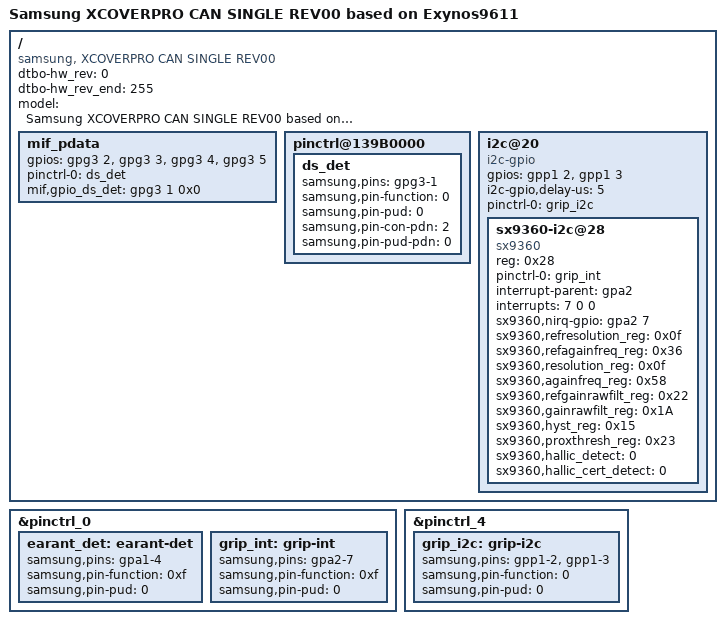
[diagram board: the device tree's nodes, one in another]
/*
 * SAMSUNG EXYNOS9610 board device tree source
 *
 * Copyright (c) 2018 Samsung Electronics Co., Ltd.
 *		http://www.samsung.com
 *
 * This program is free software; you can redistribute it and/or modify
 * it under the terms of the GNU General Public License version 2 as
 * published by the Free Software Foundation.
 */

/dts-v1/;
/plugin/;
#include "exynos9611-xcoverpro_common.dtsi"
#include "battery_data_xcoverpro_usa_open_00.dtsi"
#include "exynos9611-xcoverpro_fingerprint_00.dtsi"
#include "exynos9611-xcoverpro_sensorhub_00.dtsi"
#include "exynos9611-xcoverpro_nfc_00.dtsi"
#include "exynos9611-xcoverpro_can_single_gpio_00.dtsi"

/ {
	compatible = "samsung, XCOVERPRO CAN SINGLE REV00", "samsung,EXYNOS9611";
	dtbo-hw_rev = <0>;
	dtbo-hw_rev_end = <255>;

	fragment@model {
		target-path = "/";
		__overlay__ {
			#address-cells = <2>;
			#size-cells = <1>;

			model = "Samsung XCOVERPRO CAN SINGLE REV00 based on Exynos9611";

			mif_pdata {
				/* GPIOs for HW REV */
				/* XGPIO26-AP_REV0, XGPIO27-AP_REV1, XGPIO28-AP_REV2, XGPIO29-AP_REV3 */
				gpios = <&gpg3 2 0>, <&gpg3 3 0>, <&gpg3 4 0>, <&gpg3 5 0>;
				pinctrl-names = "default";

				pinctrl-0 = <&ds_det>;
				mif,gpio_ds_det = <&gpg3 1 0x0>;
			};

			pinctrl@139B0000 {
				ds_det: ds_det {
					samsung,pins = "gpg3-1";
					samsung,pin-function = <0>;	/* INPUT */
					samsung,pin-pud = <0>;
					samsung,pin-con-pdn = <2>;	/* INPUT */
					samsung,pin-pud-pdn = <0>;
				};
			};

			i2c@20 {
				compatible = "i2c-gpio";
				gpios = <&gpp1 2 0
						&gpp1 3 0>;
				i2c-gpio,delay-us = <5>;
				#address-cells = <1>;
				#size-cells = <0>;
				pinctrl-names = "default";
				pinctrl-0 = <&grip_i2c>;

				sx9360-i2c@28 {
					status = "okay";

					compatible = "sx9360";
					reg = <0x28>;
					pinctrl-names = "default";
					pinctrl-0 = <&grip_int>;
					interrupt-parent = <&gpa2>;
					interrupts = <7 0 0>;
					sx9360,nirq-gpio = <&gpa2 7 0>;

					sx9360,refresolution_reg = <0x0f>; /* same as resolution_reg */
					sx9360,refagainfreq_reg = <0x36>; /* same as againfreq_reg */
					sx9360,resolution_reg = <0x0f>; /* resolution : 1024 */
					sx9360,againfreq_reg = <0x58>; /* freq : 62.5 kHz, again : +/-7.5 pF */
					sx9360,refgainrawfilt_reg = <0x22>; /* same as gainrawfilt_reg */
					sx9360,gainrawfilt_reg = <0x1A>; /* rawfilter : 1-1/4, gain : x4 */
					sx9360,hyst_reg = <0x15>; /* hysteresis : +/-6 %, debouncer : 2 samples */
					sx9360,proxthresh_reg = <0x23>; /* threshhold : 612 */
					sx9360,hallic_detect = <0>;
					sx9360,hallic_cert_detect = <0>;
				};
			};
		}; /* end of __overlay__ */
	}; /* end of fragment */
}; /* end of root */

&pinctrl_0 {
	earant_det: earant-det {
		samsung,pins ="gpa1-4";
		samsung,pin-function = <0xf>;
		samsung,pin-pud = <0>;
	};

	grip_int: grip-int {
		samsung,pins = "gpa2-7";
		samsung,pin-function = <0xf>;
		samsung,pin-pud = <0>;
	};
};

&pinctrl_4 {
	grip_i2c: grip-i2c {
		samsung,pins = "gpp1-2", "gpp1-3";
		samsung,pin-function = <0>;
		samsung,pin-pud = <0>;
	};
};
